AUTOSAR XML (schema 4-0-3)
standard types defined: uint8, UInt8
package /AUTOSAR_Platform/DataConstrs
  range DC_UInt8: raw 0..255
package /PATAC/MSM/ComponentTypes
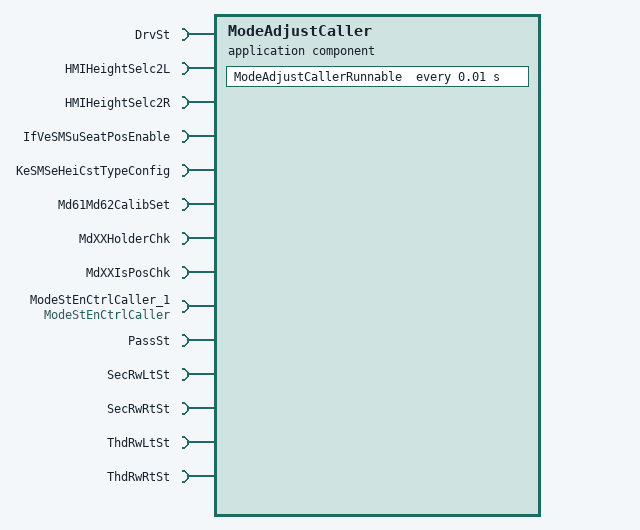
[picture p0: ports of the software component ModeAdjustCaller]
  application sw component type ModeAdjustCaller
    14 x require port:
      DrvSt: client-com-spec=DrvSt/Cal, required-interface=DrvSt
      HMIHeightSelc2L: client-com-spec=HMIHeightSelc2L/Cal, required-interface=HMIHeightSelc2L
      HMIHeightSelc2R: client-com-spec=HMIHeightSelc2R/Cal, required-interface=HMIHeightSelc2R
      IfVeSMSuSeatPosEnable: nonqueued-receiver-com-spec{data-element=Val, filter=data-filter-type=ALWAYS, init-value=0}, required-interface=IfVeSMSuSeatPosEnable
      KeSMSeHeiCstTypeConfig: parameter-require-com-spec{init-value=0, parameter=Val}, required-interface=KeSMSeHeiCstTypeConfig
      Md61Md62CalibSet: client-com-spec=Md61Md62CalibSet/Cal, required-interface=Md61Md62CalibSet
      MdXXHolderChk: client-com-spec=MdXXHolderChk/Cal, required-interface=MdXXHolderChk
      MdXXIsPosChk: client-com-spec=MdXXIsPosChk/Cal, required-interface=MdXXIsPosChk
      ModeStEnCtrlCaller_1: client-com-spec=ModeStEnCtrlCaller/Cal, required-interface=ModeStEnCtrlCaller
      PassSt: client-com-spec=PassSt/Cal, required-interface=PassSt
      SecRwLtSt: client-com-spec=SecRwLtSt/Cal, required-interface=SecRwLtSt
      SecRwRtSt: client-com-spec=SecRwRtSt/Cal, required-interface=SecRwRtSt
      ThdRwLtSt: client-com-spec=ThdRwLtSt/Cal, required-interface=ThdRwLtSt
      ThdRwRtSt: client-com-spec=ThdRwRtSt/Cal, required-interface=ThdRwRtSt
    behavior ModeAdjustCaller_InternalBehavior
      timing event TMT_ModeAdjustCallerRunnable: start-on-event=ModeAdjustCallerRunnable, period=0.01
      runnable ModeAdjustCallerRunnable
        data-receive-point-by-arguments:
          access REC_IfVeSMSuSeatPosEnable_Val: accessed-variable=IfVeSMSuSeatPosEnable.Val
        parameter access PA_KeSMSeHeiCstTypeConfig_Val: accessed-parameter=KeSMSeHeiCstTypeConfig.Val
        12 x sync call, all with timeout=0:
          SC_DrvSt_Cal: operation=DrvSt.Cal
          SC_HMIHeightSelc_Cal: operation=HMIHeightSelc2L.Cal
          SC_HMIHeightSelc2R_Cal: operation=HMIHeightSelc2R.Cal
          SC_Md61Md62CalibSet_Cal: operation=Md61Md62CalibSet.Cal
          SC_MdXXHolderChk_Cal: operation=MdXXHolderChk.Cal
          SC_MdXXIsPosChk_Cal: operation=MdXXIsPosChk.Cal
          SC_ModeStEnCtrlCaller_1_Cal: operation=ModeStEnCtrlCaller_1.Cal
          SC_PassSt_Cal: operation=PassSt.Cal
          SC_SecRwLtSt_Cal: operation=SecRwLtSt.Cal
          SC_SecRwRtSt_Cal: operation=SecRwRtSt.Cal
          SC_ThdRwLtSt_Cal: operation=ThdRwLtSt.Cal
          SC_ThdRwRtSt_Cal: operation=ThdRwRtSt.Cal
  swc implementation ModeAdjustCaller_Implementation: behavior=ModeAdjustCaller_InternalBehavior
    code-descriptors:
      code Default: artifact-descriptors=autosar-engineering-object={short-label=Default, category=SWSRC}
package /PATAC/MSM/ModeAdjust/CalPortInterface
  parameter interface KeSMSeHeiCstTypeConfig
    parameter data prototype Val: sw-calibration-access=READ-WRITE, type=UInt8
package /PATAC/MSM/ModeAdjust/PortInterface
  12 x client server interface:
    DrvSt
      operation Cal
    HMIHeightSelc2L
      operation Cal
    HMIHeightSelc2R
      operation Cal
    Md61Md62CalibSet
      operation Cal
    MdXXHolderChk
      operation Cal
    MdXXIsPosChk
      operation Cal
    ModeStEnCtrlCaller
      operation Cal
    PassSt
      operation Cal
    SecRwLtSt
      operation Cal
    SecRwRtSt
      operation Cal
    ThdRwLtSt
      operation Cal
    ThdRwRtSt
      operation Cal
package /PATAC/MSM/PortInterfaces
  sender receiver interface IfVeSMSuSeatPosEnable: invalidation-policy{data-element=Val, handle-invalid=DONT-INVALIDATE}
    data Val: type=UInt8
